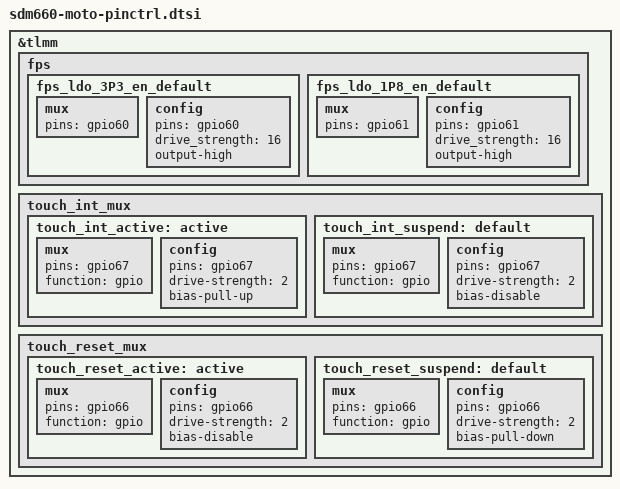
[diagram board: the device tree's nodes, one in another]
/* Copyright (c) 2016, Motorola Mobility Inc. All rights reserved.
 *
 * This program is free software; you can redistribute it and/or modify
 * it under the terms of the GNU General Public License version 2 and
 * only version 2 as published by the Free Software Foundation.
 *
 * This program is distributed in the hope that it will be useful,
 * but WITHOUT ANY WARRANTY; without even the implied warranty of
 * MERCHANTABILITY or FITNESS FOR A PARTICULAR PURPOSE.  See the
 * GNU General Public License for more details.
 */

&tlmm {
	fps {
		fps_ldo_3P3_en_default: fps_ldo_3P3_en_default {
			mux {
				pins = "gpio60";
			};
			config {
				pins = "gpio60";
				drive_strength = <16>;
				output-high;
			};
		};
		fps_ldo_1P8_en_default: fps_ldo_1P8_en_default {
			mux {
				pins = "gpio61";
			};
			config {
				pins = "gpio61";
				drive_strength = <16>;
				output-high;
			};
		};
	};

	touch_int_mux {
		touch_int_active: active {
			mux {
				pins = "gpio67";
				function = "gpio";
			};
			config {
				pins = "gpio67";
				drive-strength = <2>;
				bias-pull-up;
			};
		};

		touch_int_suspend: default {
			mux {
				pins = "gpio67";
				function = "gpio";
			};
			config {
				pins = "gpio67";
				drive-strength = <2>;
				bias-disable;
			};
		};
	};

	touch_reset_mux {
		touch_reset_active: active {
			mux {
				pins = "gpio66";
				function = "gpio";
			};
			config {
				pins = "gpio66";
				drive-strength = <2>;
				bias-disable;
			};
		};

		touch_reset_suspend: default {
			mux {
				pins = "gpio66";
				function = "gpio";
			};
			config {
				pins = "gpio66";
				drive-strength = <2>;
				bias-pull-down;
			};
		};
	};
};
